# PIC32CM6408PL10064 device description
Architecture: CORTEX-M0PLUS; Family: PIC32CMPL; Series: PIC32CMPL10
Registers are 32-bit, read-write, reset 0x0 unless marked. A register's access mark holds for its fields unless they carry their own. Offsets are from the block's base; [hi:lo] are bit positions; {n}, {i} and the like mark numbered series; 'fields as' and 'values as' point back to an identical list.

## DMAC_DESCRIPTOR — Direct Memory Access Controller
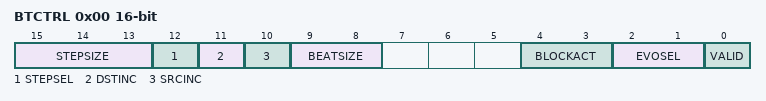
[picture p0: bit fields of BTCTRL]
0x00 BTCTRL 16-bit — Block Transfer Control
  [15:13] STEPSIZE — Address Increment Step Size
    0=Next ADDR = ADDR + (Beat size in byte) * 1; 1=X2 (Next ADDR = ADDR + (Beat size in byte) * 2); 2=X4 (Next ADDR = ADDR + (Beat size in byte) * 4); 3=X8 (Next ADDR = ADDR + (Beat size in byte) * 8); 4=X16 (Next ADDR = ADDR + (Beat size in byte) * 16); 5=X32 (Next ADDR = ADDR + (Beat size in byte) * 32); 6=X64 (Next ADDR = ADDR + (Beat size in byte) * 64); 7=X128 (Next ADDR = ADDR + (Beat size in byte) * 128)
  [12] STEPSEL — Step Selection
    0=DST (Step size settings apply to the destination address); 1=SRC (Step size settings apply to the source address)
  [11] DSTINC — Destination Address Increment Enable
  [10] SRCINC — Source Address Increment Enable
  [9:8] BEATSIZE
    0=BYTE (8-bit); 1=HWORD (16-bit); 2=WORD (32-bit)
  [4:3] BLOCKACT — Block Action
    0=NOACT (Channel will be disabled if it is the last block transfer in the transaction); 1=INT (Channel will be disabled if it is the last block transfer in the transaction and block interrupt); 2=SUSPEND (Channel suspend operation is completed); 3=BOTH (Both channel suspend operation and block interrupt)
  [2:1] EVOSEL — Event Output Selection
    0=DISABLE (Event generation disabled); 1=BLOCK (Event strobe when block transfer complete); 3=BEAT (Event strobe when beat transfer complete)
  [0] VALID — Descriptor Valid
0x02 BTCNT 16-bit — Block Transfer Count
0x04 SRCADDR — Block Transfer Source Address
  [31:0] SRCADDR — Transfer Source Address
0x08 DSTADDR — Block Transfer Destination Address
  [31:0] DSTADDR — Transfer Destination Address
0x0C DESCADDR — Next Descriptor Address

## DSU — Device Service Unit
Instances: DSU 0x41002000
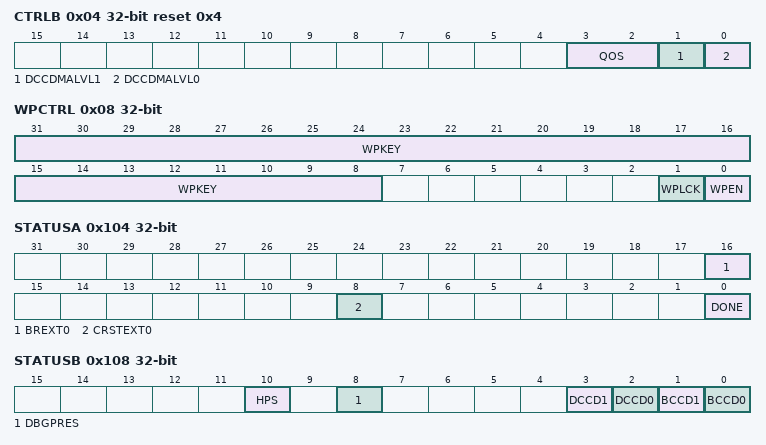
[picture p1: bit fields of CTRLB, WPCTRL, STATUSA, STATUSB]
0x04 CTRLB reset 0x4 — Control B
  [3:2] QOS — DSU QoS Level
    0=DISABLE (Background (no sensitive operation)); 1=LOW (Sensitive bandwidth); 2=MEDIUM (Sensitive latency); 3=HIGH (Critical latency)
  [1] DCCDMALVL1 — DMA Trigger 1 Level
    0=EMPTY (Trigger n rises when DCCn is read and falls when it is written); 1=FULL (Trigger n rises when DCCn is written and falls when it is read)
  [0] DCCDMALVL0 — DMA Trigger 0 Level
    values as DCCDMALVL1
0x08 WPCTRL — Write Protection Control
  [31:8] WPKEY — Write Protection Key
    0x445355=KEY (Allow writes to the WPCTRL register)
  [1] WPLCK — Write Protection Lock
  [0] WPEN — Write Protection Enable
0x100 CTRLC — Control C
  [0] DBGRW0 — CPU0 Debug R/W
0x104 STATUSA ro
  [16] BREXT0 — Boot ROM 0 Phase Extension Status
  [8] CRSTEXT0 — CPU0 Reset Extension Status
  [0] DONE — Done Status
0x108 STATUSB ro
  [10] HPS — Hot-plugging Status
  [8] DBGPRES — Debugger Present Status
  [3] DCCD1 — Debug Communication Channel 1 Dirty
  [2] DCCD0 — Debug Communication Channel 0 Dirty
  [1] BCCD1 — Boot ROM Communication Channel 1 Dirty
  [0] BCCD0 — Boot ROM Communication Channel 0 Dirty
{0x110+4i} BCC[{i}] (i=0..1) reset not defined — Boot ROM Channel #
  [31:0] DATA
{0x118+4i} DCC[{i}] (i=0..1) reset not defined — Debug Communication Channel #
  [31:0] DATA
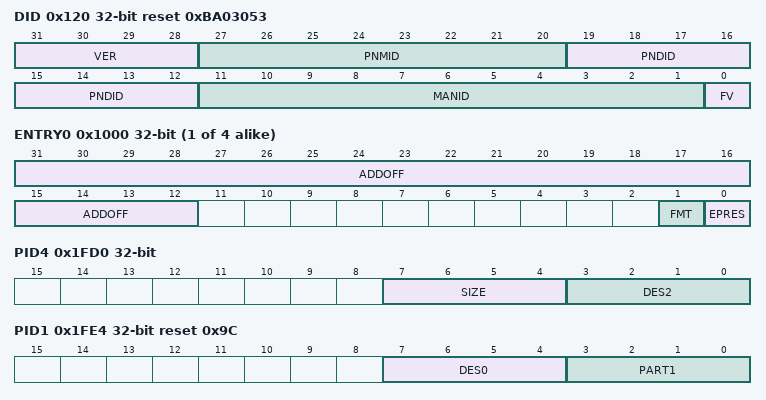
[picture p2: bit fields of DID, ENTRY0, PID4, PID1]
0x120 DID ro reset 0xBA03053 — Device Identification
  [31:28] VER — Version Code
  [27:20] PNMID — Part Number Mask ID
  [19:12] PNDID — Part Number Device ID
  [11:1] MANID — JEDEC Manufacture ID
  [0] FV — Fixed Value of 1
0x124 DAL ro reset not defined — Debugger Access Level
  [1:0] CPU0 — CPU 0 Debugger Access Level
    0=SECURED (The Debugger targeting the CPU0 domain can only access the DSU external address space; otherwise, debugger access is disabled.); 2=FULL_DEBUG (The Debugger has unrestricted access)
{0x1000+4i} ENTRY{i} ro reset not defined (i=0..3) — CoreSight ROM Table Entry {i}
  [31:12] ADDOFF — CoreSight ROM Table Address Offset
  [1] FMT — CoreSight Rom Table Format
  [0] EPRES — CoreSight Entry Present
0x1FCC MEMTYPE ro — CoreSight ROM Table Memory Type
  [0] SYSMEM — CoreSight System Memory Present
0x1FD0 PID4 ro — CoreSight Peripheral Identification 4
  [7:4] SIZE — CoreSight Size
  [3:0] DES2 — CoreSight JEP-106 Continuation Code
{0x1FC0+4i} PID{i} ro (i=5..7) — CoreSight Peripheral Identification {i}
  [7:0] RES0 — CoreSight Reserved Field
0x1FE0 PID0 ro reset 0xD0 — CoreSight Peripheral Identification 0
  [7:0] PART0 — CoreSight Part Number Bits
0x1FE4 PID1 ro reset 0x9C — CoreSight Peripheral Identification 1
  [7:4] DES0 — CoreSight JEP106 Identification Code Bits
  [3:0] PART1 — CoreSight Part Number Bits
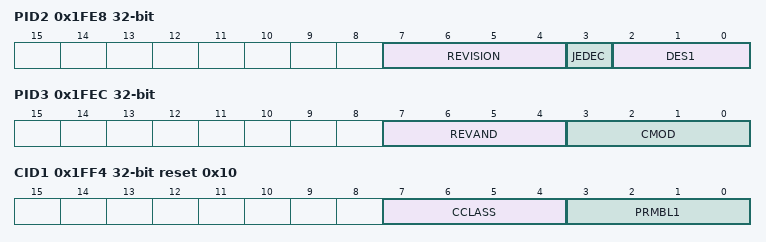
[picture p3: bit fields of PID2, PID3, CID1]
0x1FE8 PID2 ro reset not defined — CoreSight Peripheral Identification 2
  [7:4] REVISION — CoreSight Revision Number
  [3] JEDEC — CoreSight JEDEC Assignment
  [2:0] DES1 — CoreSight JEP106 Identification Code Bits
0x1FEC PID3 ro — CoreSight Peripheral Identification 3
  [7:4] REVAND — CoreSight REVAND
  [3:0] CMOD — CoreSight Custom Modifier 0
0x1FF0 CID0 ro reset 0xD — CoreSight Component Identification 0
  [7:0] PRMBL0 — CoreSight Preamble 0
0x1FF4 CID1 ro reset 0x10 — CoreSight Component Identification 1
  [7:4] CCLASS — CoreSight Component Class
  [3:0] PRMBL1 — CoreSight Preamble 1
0x1FF8 CID2 ro reset 0x5 — CoreSight Component Identification 2
  [7:0] PRMBL2 — CoreSight Preamble 2
0x1FFC CID3 ro reset 0xB1 — CoreSight Component Identification 3
  [7:0] PRMBL3 — CoreSight Preamble 3
